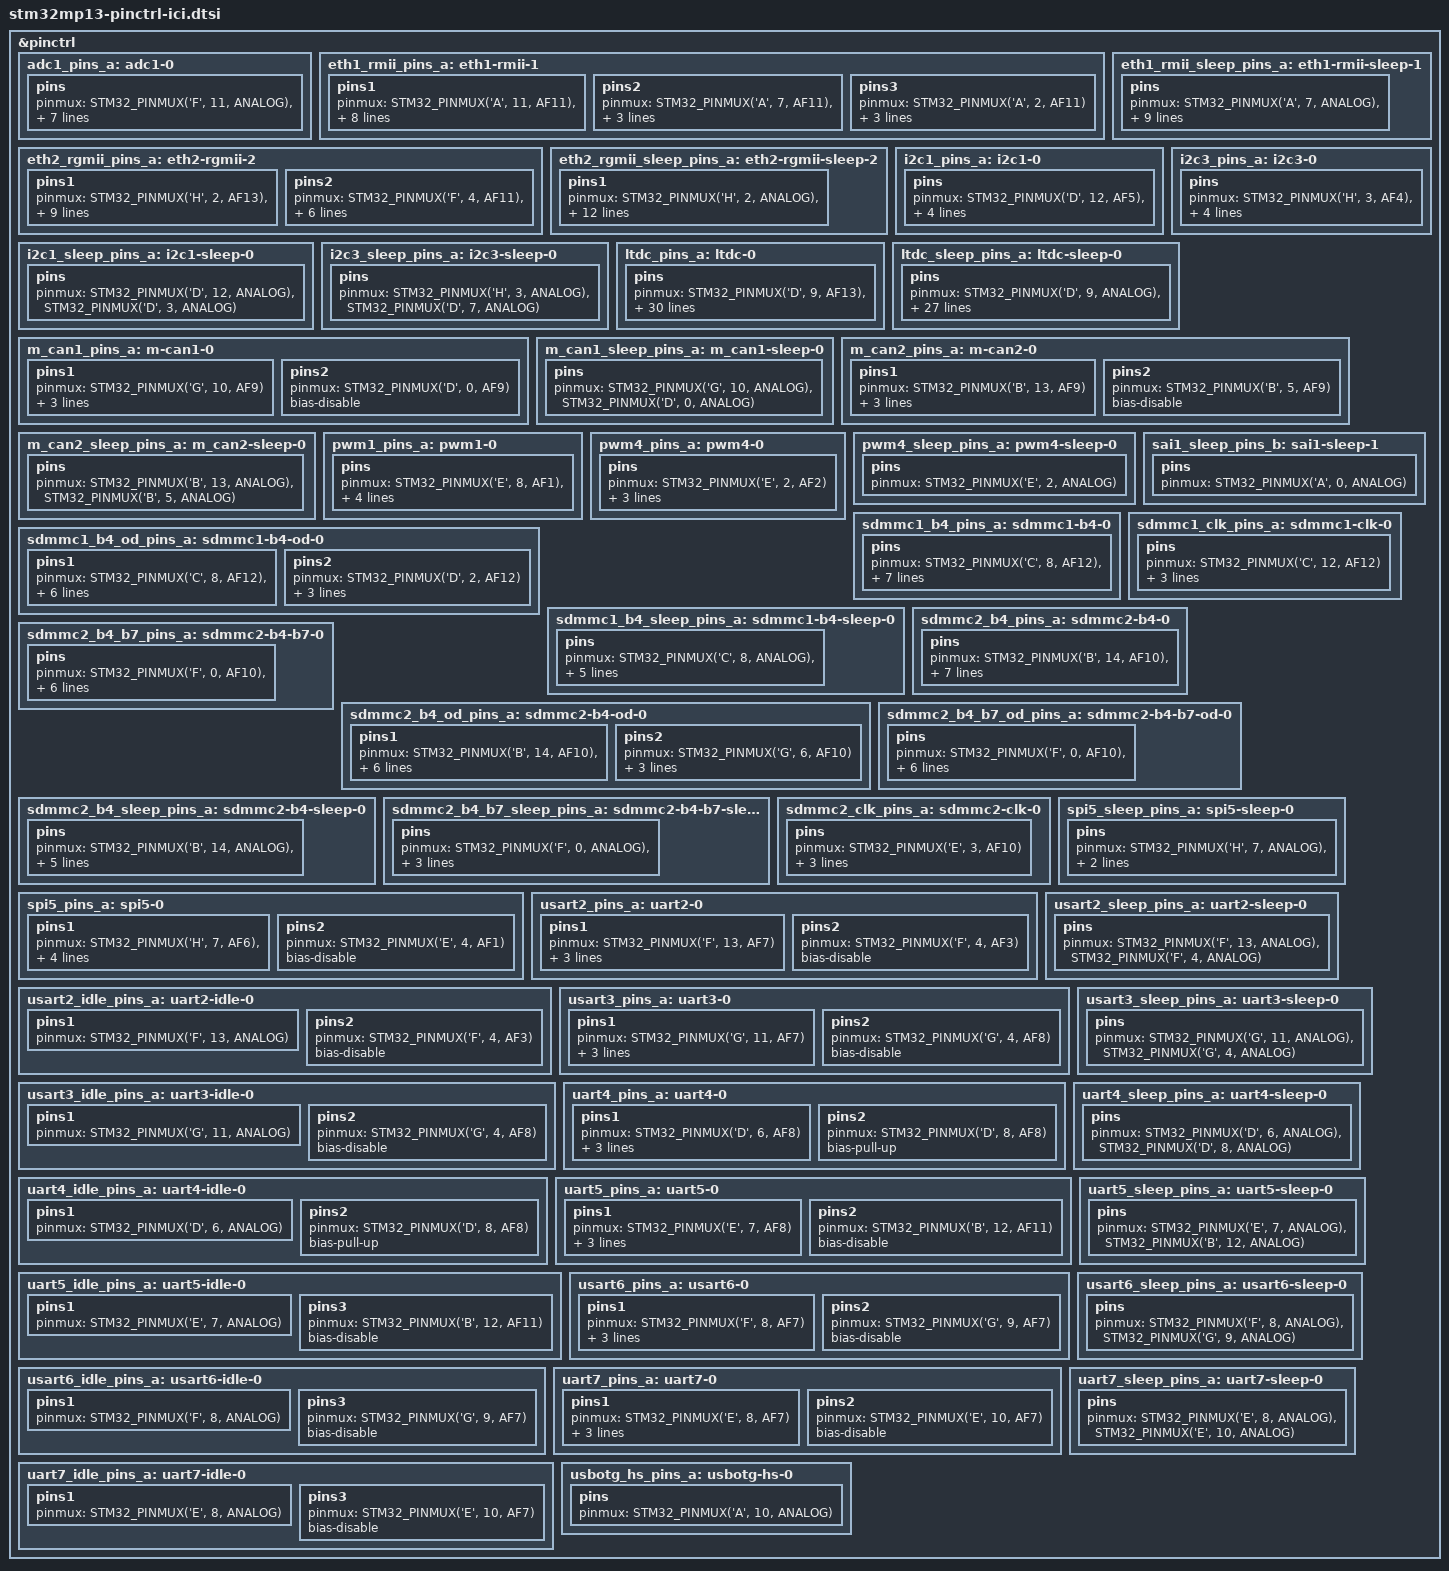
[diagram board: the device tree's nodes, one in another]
// SPDX-License-Identifier: (GPL-2.0+ OR BSD-3-Clause)
/*
 * Copyright (C) STMicroelectronics 2021 - All Rights Reserved
 * Author: Alexandre Torgue <alexandre.torgue@foss.st.com>
 */
#include <dt-bindings/pinctrl/stm32-pinfunc.h>

&pinctrl {
	adc1_pins_a: adc1-0 {
		pins {
			pinmux = <STM32_PINMUX('F', 11, ANALOG)>, /* ADC1 inp8 */
					<STM32_PINMUX('A', 0, ANALOG)>, /* ADC1 inp7 */
					<STM32_PINMUX('A', 5, ANALOG)>, /* ADC1 inp2 */
					<STM32_PINMUX('C', 0, ANALOG)>, /* ADC1 inp0 */
					<STM32_PINMUX('A', 4, ANALOG)>, /* ADC1 inp14 */
					<STM32_PINMUX('B', 1, ANALOG)>, /* ADC1 inp5 */
					<STM32_PINMUX('C', 3, ANALOG)>, /* ADC1 inp13 */
					<STM32_PINMUX('A', 3, ANALOG)>; /* ADC1 inp12 */
		};
	};

	eth1_rmii_pins_a: eth1-rmii-1 {
		pins1 {
			pinmux = <STM32_PINMUX('A', 11, AF11)>, /* ETH1_CLK */
					 <STM32_PINMUX('B', 11, AF11)>, /* ETH1_TX_EN */
					 <STM32_PINMUX('A', 1, AF11)>, /* ETH1_REF_CLK */
					 <STM32_PINMUX('G', 2, AF11)>, /* ETH1_MDC */
					 <STM32_PINMUX('G', 13, AF11)>, /* ETH1_TXD0 */
					 <STM32_PINMUX('G', 14, AF11)>; /* ETH1_TXD1 */
			bias-disable;
			drive-push-pull;
			slew-rate = <1>;
		};
		pins2 {
			pinmux = <STM32_PINMUX('A', 7, AF11)>, /* ETH1_CRS_DV */
					 <STM32_PINMUX('C', 4, AF11)>, /* ETH1_RXD0 */
					 <STM32_PINMUX('C', 5, AF11)>; /* ETH1_RXD1 */
			bias-disable;
		};
		pins3 {
			pinmux = <STM32_PINMUX('A', 2, AF11)>; /* ETH1_MDIO */
			bias-disable;
			drive-push-pull;
			slew-rate = <0>;
		};
	};

	eth1_rmii_sleep_pins_a: eth1-rmii-sleep-1 {
		pins {
			pinmux = <STM32_PINMUX('A', 7, ANALOG)>, /* ETH1_CRS_DV */
					 <STM32_PINMUX('A', 11, ANALOG)>, /* ETH1_CLK */
					 <STM32_PINMUX('B', 11, ANALOG)>, /* ETH1_TX_EN */
					 <STM32_PINMUX('C', 4, ANALOG)>, /* ETH1_RXD0 */
					 <STM32_PINMUX('C', 5, ANALOG)>, /* ETH1_RXD1 */
					 <STM32_PINMUX('A', 1, ANALOG)>, /* ETH1_REF_CLK */
					 <STM32_PINMUX('G', 2, ANALOG)>, /* ETH1_MDC */
					 <STM32_PINMUX('A', 2, ANALOG)>, /* ETH1_MDIO */
					 <STM32_PINMUX('G', 13, ANALOG)>, /* ETH1_TXD0 */
					 <STM32_PINMUX('G', 14, ANALOG)>; /* ETH1_TXD1 */
		};
	};

	eth2_rgmii_pins_a: eth2-rgmii-2 {
		pins1 {
			pinmux = <STM32_PINMUX('H', 2, AF13)>, /* ETH2_RGMII_CLK125 */
				 //<STM32_PINMUX('F', 7, AF11)>, 	/* ETH2_RGMII_TXD0 */
				 <STM32_PINMUX('G', 11, AF10)>, /* ETH2_RGMII_TXD1 */
				 <STM32_PINMUX('G', 1, AF10)>, 	/* ETH2_RGMII_TXD2 */
				 <STM32_PINMUX('E', 6, AF11)>, 	/* ETH2_RGMII_TXD3 */
				 <STM32_PINMUX('G', 3, AF10)>, 	/* ETH2_RGMII_GTX_CLK */
				 //<STM32_PINMUX('F', 6, AF11)>, 	/* ETH2_RGMII_TX_CTL */
				 <STM32_PINMUX('B', 2, AF11)>, 	/* ETH2_MDIO */
				 <STM32_PINMUX('G', 5, AF10)>; 	/* ETH2_MDC */
			bias-disable;
			drive-push-pull;
			slew-rate = <2>;
		};

		pins2 {
			pinmux = <STM32_PINMUX('F', 4, AF11)>, /* ETH2_RGMII_RXD0 */
				 <STM32_PINMUX('E', 2, AF10)>, 	/* ETH2_RGMII_RXD1 */
				 <STM32_PINMUX('H', 6, AF12)>, 	/* ETH2_RGMII_RXD2 */
				 <STM32_PINMUX('A', 8, AF11)>, 	/* ETH2_RGMII_RXD3 */
				 <STM32_PINMUX('H', 11, AF11)>, /* ETH2_RGMII_RX_CLK */
				 <STM32_PINMUX('G', 12, AF12)>; /* ETH2_RGMII_RX_CTL */
			bias-disable;
		};
	};

	eth2_rgmii_sleep_pins_a: eth2-rgmii-sleep-2 {
		pins1 {
			pinmux = <STM32_PINMUX('H', 2, ANALOG)>, /* ETH2_RGMII_CLK125 */
				 //<STM32_PINMUX('F', 7, ANALOG)>, 	/* ETH2_RGMII_TXD0 */
				 <STM32_PINMUX('G', 11, ANALOG)>, 	/* ETH2_RGMII_TXD1 */
				 <STM32_PINMUX('G', 1, ANALOG)>, 	/* ETH2_RGMII_TXD2 */
				 <STM32_PINMUX('E', 6, ANALOG)>, 	/* ETH2_RGMII_TXD3 */
				 <STM32_PINMUX('G', 3, ANALOG)>, 	/* ETH2_RGMII_GTX_CLK */
				 //<STM32_PINMUX('F', 6, ANALOG)>, 	/* ETH2_RGMII_TX_CTL */
				 <STM32_PINMUX('B', 2, ANALOG)>, 	/* ETH2_MDIO */
				 <STM32_PINMUX('G', 5, ANALOG)>, 	/* ETH2_MDC */
				 <STM32_PINMUX('F', 4, ANALOG)>, 	/* ETH2_RGMII_RXD0 */
				 <STM32_PINMUX('E', 2, ANALOG)>, 	/* ETH2_RGMII_RXD1 */
				 <STM32_PINMUX('H', 6, ANALOG)>, 	/* ETH2_RGMII_RXD2 */
				 <STM32_PINMUX('A', 8, ANALOG)>, 	/* ETH2_RGMII_RXD3 */
				 <STM32_PINMUX('H', 11, ANALOG)>, 	/* ETH2_RGMII_RX_CLK */
				 <STM32_PINMUX('G', 12, ANALOG)>; 	/* ETH2_RGMII_RX_CTL */
		};
	};

	i2c1_pins_a: i2c1-0 {
		pins {
			pinmux = <STM32_PINMUX('D', 12, AF5)>, /* I2C1_SCL */
				 <STM32_PINMUX('D', 3, AF5)>; /* I2C1_SDA */
			bias-disable;
			drive-open-drain;
			slew-rate = <0>;
		};
	};

	i2c1_sleep_pins_a: i2c1-sleep-0 {
		pins {
			pinmux = <STM32_PINMUX('D', 12, ANALOG)>, /* I2C1_SCL */
				 <STM32_PINMUX('D', 3, ANALOG)>; /* I2C1_SDA */
		};
	};

	i2c3_pins_a: i2c3-0 {
		pins {
			pinmux = <STM32_PINMUX('H', 3, AF4)>, /* I2C3_SCL */
				 <STM32_PINMUX('D', 7, AF5)>; /* I2C3_SDA */
			bias-disable;
			drive-open-drain;
			slew-rate = <0>;
		};
	};

	i2c3_sleep_pins_a: i2c3-sleep-0 {
		pins {
			pinmux = <STM32_PINMUX('H', 3, ANALOG)>, /* I2C3_SCL */
				 <STM32_PINMUX('D', 7, ANALOG)>; /* I2C3_SDA */
		};
	};

	ltdc_pins_a: ltdc-0 {
		pins {
			pinmux = <STM32_PINMUX('D',  9, AF13)>, /* LCD_CLK */
				 <STM32_PINMUX('H',  10, AF13)>, /* LCD_HSYNC */
				 <STM32_PINMUX('G',  4, AF11)>, /* LCD_VSYNC */ 
				 <STM32_PINMUX('H',  9, AF11)>, /* LCD_DE */
				 <STM32_PINMUX('E', 11, AF9)>,  /* LCD_R0 */
				 <STM32_PINMUX('D',  4, AF11)>, /* LCD_R1 */
				 <STM32_PINMUX('G',  7, AF14)>, /* LCD_R2 */
				 <STM32_PINMUX('B', 12, AF13)>, /* LCD_R3 */
				 <STM32_PINMUX('D', 14, AF14)>, /* LCD_R4 */
				 <STM32_PINMUX('E',  7, AF14)>, /* LCD_R5 */
				 <STM32_PINMUX('E', 13, AF14)>, /* LCD_R6 */
				 <STM32_PINMUX('E',  9, AF14)>, /* LCD_R7 */
				 <STM32_PINMUX('F',  5, AF9)>,  /* LCD_G0 */
				 <STM32_PINMUX('F',  1, AF14)>, /* LCD_G1 */
				 <STM32_PINMUX('H', 13, AF14)>, /* LCD_G2 */
				 <STM32_PINMUX('F',  3, AF14)>, /* LCD_G3 */
				 <STM32_PINMUX('E', 12, AF11)>, /* LCD_G4 */
				 <STM32_PINMUX('G',  0, AF14)>, /* LCD_G5 */
				 <STM32_PINMUX('A', 12, AF14)>, /* LCD_G6 */
				 <STM32_PINMUX('A', 15, AF11)>, /* LCD_G7 */
				 <STM32_PINMUX('D',  5, AF13)>, /* LCD_B0 */
				 <STM32_PINMUX('G',  8, AF7)>,  /* LCD_B1 */
				 <STM32_PINMUX('D', 10, AF14)>, /* LCD_B2 */
				 <STM32_PINMUX('F',  2, AF14)>, /* LCD_B3 */
				 <STM32_PINMUX('G', 15, AF11)>, /* LCD_B4 */
				 <STM32_PINMUX('D', 15, AF14)>, /* LCD_B5 */
				 <STM32_PINMUX('D',  1, AF11)>, /* LCD_B6 */
				 <STM32_PINMUX('E', 15, AF14)>; /* LCD_B7 */
			bias-disable;
			drive-push-pull;
			slew-rate = <1>;
		};
	};

	ltdc_sleep_pins_a: ltdc-sleep-0 {
		pins {
			pinmux = <STM32_PINMUX('D',  9, ANALOG)>, /* LCD_CLK */
				 <STM32_PINMUX('H',  10, ANALOG)>, /* LCD_HSYNC */
				 <STM32_PINMUX('G',  4, ANALOG)>, /* LCD_VSYNC */
				 <STM32_PINMUX('H',  9, ANALOG)>, /* LCD_DE */
				 <STM32_PINMUX('E', 11, ANALOG)>, /* LCD_R0 */
				 <STM32_PINMUX('D',  4, ANALOG)>, /* LCD_R1 */				 
				 <STM32_PINMUX('G',  7, ANALOG)>, /* LCD_R2 */
				 <STM32_PINMUX('B', 12, ANALOG)>, /* LCD_R3 */
				 <STM32_PINMUX('D', 14, ANALOG)>, /* LCD_R4 */
				 <STM32_PINMUX('E',  7, ANALOG)>, /* LCD_R5 */
				 <STM32_PINMUX('E', 13, ANALOG)>, /* LCD_R6 */
				 <STM32_PINMUX('E',  9, ANALOG)>, /* LCD_R7 */
				 <STM32_PINMUX('F',  5, ANALOG)>, /* LCD_G0 */
				 <STM32_PINMUX('F',  1, ANALOG)>, /* LCD_G1 */			 
				 <STM32_PINMUX('H', 13, ANALOG)>, /* LCD_G2 */
				 <STM32_PINMUX('F',  3, ANALOG)>, /* LCD_G3 */
				 <STM32_PINMUX('E', 12, ANALOG)>, /* LCD_G4 */
				 <STM32_PINMUX('G',  0, ANALOG)>, /* LCD_G5 */
				 <STM32_PINMUX('A', 12, ANALOG)>, /* LCD_G6 */
				 <STM32_PINMUX('A', 15, ANALOG)>, /* LCD_G7 */
				 <STM32_PINMUX('D',  5, ANALOG)>, /* LCD_B0 */
				 <STM32_PINMUX('G',  8, ANALOG)>, /* LCD_B1 */			 
				 <STM32_PINMUX('D', 10, ANALOG)>, /* LCD_B2 */
				 <STM32_PINMUX('F',  2, ANALOG)>, /* LCD_B3 */
				 <STM32_PINMUX('G', 15, ANALOG)>, /* LCD_B4 */
				 <STM32_PINMUX('D', 15, ANALOG)>, /* LCD_B5 */
				 <STM32_PINMUX('D',  1, ANALOG)>, /* LCD_B6 */
				 <STM32_PINMUX('E', 15, ANALOG)>; /* LCD_B7 */
		};
	};

	m_can1_pins_a: m-can1-0 {
		pins1 {
			pinmux = <STM32_PINMUX('G', 10, AF9)>; /* CAN1_TX */
			slew-rate = <1>;
			drive-push-pull;
			bias-disable;
		};
		pins2 {
			pinmux = <STM32_PINMUX('D', 0, AF9)>; /* CAN1_RX */
			bias-disable;
		};
	};

	m_can1_sleep_pins_a: m_can1-sleep-0 {
		pins {
			pinmux = <STM32_PINMUX('G', 10, ANALOG)>, /* CAN1_TX */
				 <STM32_PINMUX('D', 0, ANALOG)>; /* CAN1_RX */
		};
	};

	m_can2_pins_a: m-can2-0 {
		pins1 {
			pinmux = <STM32_PINMUX('B', 13, AF9)>; /* CAN2_TX */
			slew-rate = <1>;
			drive-push-pull;
			bias-disable;
		};
		pins2 {
			pinmux = <STM32_PINMUX('B', 5, AF9)>; /* CAN2_RX */
			bias-disable;
		};
	};

	m_can2_sleep_pins_a: m_can2-sleep-0 {
		pins {
			pinmux = <STM32_PINMUX('B', 13, ANALOG)>, /* CAN2_TX */
				 <STM32_PINMUX('B', 5, ANALOG)>; /* CAN2_RX */
		};
	};

	pwm1_pins_a: pwm1-0 {
		pins {
			pinmux = <STM32_PINMUX('E', 8, AF1)>, /* TIM1_CH1N */
                   <STM32_PINMUX('F', 9, AF2)>; /* TIM1_CH1 */
			bias-pull-down;
			drive-push-pull;
			slew-rate = <0>;
		};
	};


	pwm4_pins_a: pwm4-0 {
		pins {
			pinmux = <STM32_PINMUX('E', 2, AF2)>; /* TIM4_CH2 */
			bias-pull-down;
			drive-push-pull;
			slew-rate = <0>;
		};
	};

	pwm4_sleep_pins_a: pwm4-sleep-0 {
		pins {
			pinmux = <STM32_PINMUX('E', 2, ANALOG)>; /* TIM4_CH2 */
		};
	};

	sai1_sleep_pins_b: sai1-sleep-1 {
		pins {
			pinmux = <STM32_PINMUX('A', 0, ANALOG)>; /* SAI1_SD_B */
		};
	};

	sdmmc1_b4_pins_a: sdmmc1-b4-0 {
		pins {
			pinmux = <STM32_PINMUX('C', 8, AF12)>, /* SDMMC1_D0 */
				 <STM32_PINMUX('C', 9, AF12)>, /* SDMMC1_D1 */
				 <STM32_PINMUX('C', 10, AF12)>, /* SDMMC1_D2 */
				 <STM32_PINMUX('C', 11, AF12)>, /* SDMMC1_D3 */
				 <STM32_PINMUX('D', 2, AF12)>; /* SDMMC1_CMD */
			slew-rate = <1>;
			drive-push-pull;
			bias-disable;
		};
	};

	sdmmc1_b4_od_pins_a: sdmmc1-b4-od-0 {
		pins1 {
			pinmux = <STM32_PINMUX('C', 8, AF12)>, /* SDMMC1_D0 */
				 <STM32_PINMUX('C', 9, AF12)>, /* SDMMC1_D1 */
				 <STM32_PINMUX('C', 10, AF12)>, /* SDMMC1_D2 */
				 <STM32_PINMUX('C', 11, AF12)>; /* SDMMC1_D3 */
			slew-rate = <1>;
			drive-push-pull;
			bias-disable;
		};
		pins2 {
			pinmux = <STM32_PINMUX('D', 2, AF12)>; /* SDMMC1_CMD */
			slew-rate = <1>;
			drive-open-drain;
			bias-disable;
		};
	};

	sdmmc1_b4_sleep_pins_a: sdmmc1-b4-sleep-0 {
		pins {
			pinmux = <STM32_PINMUX('C', 8, ANALOG)>, /* SDMMC1_D0 */
				 <STM32_PINMUX('C', 9, ANALOG)>, /* SDMMC1_D1 */
				 <STM32_PINMUX('C', 10, ANALOG)>, /* SDMMC1_D2 */
				 <STM32_PINMUX('C', 11, ANALOG)>, /* SDMMC1_D3 */
				 <STM32_PINMUX('C', 12, ANALOG)>, /* SDMMC1_CK */
				 <STM32_PINMUX('D', 2, ANALOG)>; /* SDMMC1_CMD */
		};
	};

	sdmmc1_clk_pins_a: sdmmc1-clk-0 {
		pins {
			pinmux = <STM32_PINMUX('C', 12, AF12)>; /* SDMMC1_CK */
			slew-rate = <1>;
			drive-push-pull;
			bias-disable;
		};
	};

	sdmmc2_b4_pins_a: sdmmc2-b4-0 {
		pins {
			pinmux = <STM32_PINMUX('B', 14, AF10)>, /* SDMMC2_D0 */
				 <STM32_PINMUX('B', 15, AF10)>, /* SDMMC2_D1 */
				 <STM32_PINMUX('B', 3, AF10)>, /* SDMMC2_D2 */
				 <STM32_PINMUX('B', 4, AF10)>, /* SDMMC2_D3 */
				 <STM32_PINMUX('G', 6, AF10)>; /* SDMMC2_CMD */
			slew-rate = <1>;
			drive-push-pull;
			bias-pull-up;
		};
	};

	sdmmc2_b4_b7_pins_a: sdmmc2-b4-b7-0 {
		pins {
			pinmux = <STM32_PINMUX('F', 0, AF10)>, /* SDMMC2_D4 */
				 <STM32_PINMUX('B', 9, AF10)>, /* SDMMC2_D5 */
				 <STM32_PINMUX('C', 6, AF10)>, /* SDMMC2_D6 */				 
				 <STM32_PINMUX('C', 7, AF10)>; /* SDMMC2_D7 */
			slew-rate = <1>;
			drive-push-pull;
			bias-pull-up;
		};
	};

	sdmmc2_b4_od_pins_a: sdmmc2-b4-od-0 {
		pins1 {
			pinmux = <STM32_PINMUX('B', 14, AF10)>, /* SDMMC2_D0 */
				 <STM32_PINMUX('B', 15, AF10)>, /* SDMMC2_D1 */
				 <STM32_PINMUX('B', 3, AF10)>, /* SDMMC2_D2 */
				 <STM32_PINMUX('B', 4, AF10)>; /* SDMMC2_D3 */
			slew-rate = <1>;
			drive-push-pull;
			bias-pull-up;
		};
		pins2 {
			pinmux = <STM32_PINMUX('G', 6, AF10)>; /* SDMMC2_CMD */
			slew-rate = <1>;
			drive-open-drain;
			bias-pull-up;
		};
	};

	sdmmc2_b4_b7_od_pins_a: sdmmc2-b4-b7-od-0 {
		pins {
			pinmux = <STM32_PINMUX('F', 0, AF10)>, /* SDMMC2_D4 */
				 <STM32_PINMUX('B', 9, AF10)>, /* SDMMC2_D5 */
				 <STM32_PINMUX('C', 6, AF10)>, /* SDMMC2_D6 */				 
				 <STM32_PINMUX('C', 7, AF10)>; /* SDMMC2_D7 */
			slew-rate = <1>;
			drive-push-pull;
			bias-pull-up;
		};
	};	

	sdmmc2_b4_sleep_pins_a: sdmmc2-b4-sleep-0 {
		pins {
			pinmux = <STM32_PINMUX('B', 14, ANALOG)>, /* SDMMC2_D0 */
				 <STM32_PINMUX('B', 15, ANALOG)>, /* SDMMC2_D1 */
				 <STM32_PINMUX('B', 3, ANALOG)>, /* SDMMC2_D2 */
				 <STM32_PINMUX('B', 4, ANALOG)>, /* SDMMC2_D3 */
				 <STM32_PINMUX('E', 3, ANALOG)>, /* SDMMC2_CK */
				 <STM32_PINMUX('G', 6, ANALOG)>; /* SDMMC2_CMD */
		};
	};

	sdmmc2_b4_b7_sleep_pins_a: sdmmc2-b4-b7-sleep-0 {
		pins {
			pinmux = <STM32_PINMUX('F', 0, ANALOG)>, /* SDMMC2_D4 */
				 <STM32_PINMUX('B', 9, ANALOG)>, /* SDMMC2_D5 */
				 <STM32_PINMUX('C', 6, ANALOG)>, /* SDMMC2_D6 */				 
				 <STM32_PINMUX('C', 7, ANALOG)>; /* SDMMC2_D7 */
		};
	};

	sdmmc2_clk_pins_a: sdmmc2-clk-0 {
		pins {
			pinmux = <STM32_PINMUX('E', 3, AF10)>; /* SDMMC2_CK */
			slew-rate = <1>;
			drive-push-pull;
			bias-pull-up;
		};
	};

	spi5_pins_a: spi5-0 {
		pins1 {
			pinmux = <STM32_PINMUX('H', 7, AF6)>, /* SPI5_SCK */
				 <STM32_PINMUX('H', 12, AF5)>; /* SPI5_MOSI */
			bias-disable;
			drive-push-pull;
			slew-rate = <1>;
		};

		pins2 {
			pinmux = <STM32_PINMUX('E', 4, AF1)>; /* SPI5_MISO */
			bias-disable;
		};
	};

	spi5_sleep_pins_a: spi5-sleep-0 {
		pins {
			pinmux = <STM32_PINMUX('H', 7, ANALOG)>, /* SPI5_SCK */
				 <STM32_PINMUX('E', 4, ANALOG)>, /* SPI5_MISO */
				 <STM32_PINMUX('H', 12, ANALOG)>; /* SPI5_MOSI */
		};
	};

	usart2_pins_a: uart2-0 {
		pins1 {
			pinmux = <STM32_PINMUX('F', 13, AF7)>; /* UART2_TX */
			bias-disable;
			drive-push-pull;
			slew-rate = <0>;
		};
		pins2 {
			pinmux = <STM32_PINMUX('F', 4, AF3)>; /* UART2_RX */
			bias-disable;
		};
	};

	usart2_idle_pins_a: uart2-idle-0 {
		pins1 {
			pinmux = <STM32_PINMUX('F', 13, ANALOG)>; /* UART2_TX */
		};
		pins2 {
			pinmux = <STM32_PINMUX('F', 4, AF3)>; /* UART2_RX */
			bias-disable;
		};
	};

	usart2_sleep_pins_a: uart2-sleep-0 {
		pins {
			pinmux = <STM32_PINMUX('F', 13, ANALOG)>, /* UART2_TX */
				 <STM32_PINMUX('F', 4, ANALOG)>; /* UART2_RX */
		};
	};

	usart3_pins_a: uart3-0 {
		pins1 {
			pinmux = <STM32_PINMUX('G', 11, AF7)>; /* UART3_TX */
			bias-disable;
			drive-push-pull;
			slew-rate = <0>;
		};
		pins2 {
			pinmux = <STM32_PINMUX('G', 4, AF8)>; /* UART3_RX */
			bias-disable;
		};
	};

	usart3_idle_pins_a: uart3-idle-0 {
		pins1 {
			pinmux = <STM32_PINMUX('G', 11, ANALOG)>; /* UART3_TX */
		};
		pins2 {
			pinmux = <STM32_PINMUX('G', 4, AF8)>; /* UART3_RX */
			bias-disable;
		};
	};

	usart3_sleep_pins_a: uart3-sleep-0 {
		pins {
			pinmux = <STM32_PINMUX('G', 11, ANALOG)>, /* UART3_TX */
				 <STM32_PINMUX('G', 4, ANALOG)>; /* UART3_RX */
		};
	};

	uart4_pins_a: uart4-0 {
		pins1 {
			pinmux = <STM32_PINMUX('D', 6, AF8)>; /* UART4_TX */
			bias-disable;
			drive-push-pull;
			slew-rate = <0>;
		};
		pins2 {
			pinmux = <STM32_PINMUX('D', 8, AF8)>; /* UART4_RX */
			bias-pull-up;
		};
	};

	uart4_idle_pins_a: uart4-idle-0 {
		pins1 {
			pinmux = <STM32_PINMUX('D', 6, ANALOG)>; /* UART4_TX */
		};
		pins2 {
			pinmux = <STM32_PINMUX('D', 8, AF8)>; /* UART4_RX */
			bias-pull-up;
		};
	};

	uart4_sleep_pins_a: uart4-sleep-0 {
		pins {
			pinmux = <STM32_PINMUX('D', 6, ANALOG)>, /* UART4_TX */
				 <STM32_PINMUX('D', 8, ANALOG)>; /* UART4_RX */
		};
	};

	uart5_pins_a: uart5-0 {
		pins1 {
			pinmux = <STM32_PINMUX('E', 7, AF8)>; /* UART5_TX */
			bias-disable;
			drive-push-pull;
			slew-rate = <0>;
		};
		pins2 {
			pinmux = <STM32_PINMUX('B', 12, AF11)>; /* UART5_RX */
			bias-disable;
		};
	};

	uart5_idle_pins_a: uart5-idle-0 {
		pins1 {
			pinmux = <STM32_PINMUX('E', 7, ANALOG)>; /* UART5_TX */
		};
		pins3 {
			pinmux = <STM32_PINMUX('B', 12, AF11)>; /* UART5_RX */
			bias-disable;
		};
	};

	uart5_sleep_pins_a: uart5-sleep-0 {
		pins {
			pinmux = <STM32_PINMUX('E', 7, ANALOG)>, /* UART5_TX */
				 <STM32_PINMUX('B', 12, ANALOG)>; /* UART5_RX */
		};
	};

	usart6_pins_a: usart6-0 {
		pins1 {
			pinmux = <STM32_PINMUX('F', 8, AF7)>; /* UART6_TX */
			bias-disable;
			drive-push-pull;
			slew-rate = <0>;
		};
		pins2 {
			pinmux = <STM32_PINMUX('G', 9, AF7)>; /* UART6_RX */
			bias-disable;
		};
	};

	usart6_idle_pins_a: usart6-idle-0 {
		pins1 {
			pinmux = <STM32_PINMUX('F', 8, ANALOG)>; /* UART6_TX */
		};
		pins3 {
			pinmux = <STM32_PINMUX('G', 9, AF7)>; /* UART6_RX */
			bias-disable;
		};
	};

	usart6_sleep_pins_a: usart6-sleep-0 {
		pins {
			pinmux = <STM32_PINMUX('F', 8, ANALOG)>, /* UART6_TX */
				 <STM32_PINMUX('G', 9, ANALOG)>; /* UART6_RX */
		};
	};

	uart7_pins_a: uart7-0 {
		pins1 {
			pinmux = <STM32_PINMUX('E', 8, AF7)>; /* UART7_TX */
			bias-disable;
			drive-push-pull;
			slew-rate = <0>;
		};
		pins2 {
			pinmux = <STM32_PINMUX('E', 10, AF7)>; /* UART7_RX */
			bias-disable;
		};
	};

	uart7_idle_pins_a: uart7-idle-0 {
		pins1 {
			pinmux = <STM32_PINMUX('E', 8, ANALOG)>; /* UART7_TX */
		};
		pins3 {
			pinmux = <STM32_PINMUX('E', 10, AF7)>; /* UART7_RX */
			bias-disable;
		};
	};

	uart7_sleep_pins_a: uart7-sleep-0 {
		pins {
			pinmux = <STM32_PINMUX('E', 8, ANALOG)>, /* UART7_TX */
				 <STM32_PINMUX('E', 10, ANALOG)>; /* UART7_RX */
		};
	};

	usbotg_hs_pins_a: usbotg-hs-0 {
		pins {
			pinmux = <STM32_PINMUX('A', 10, ANALOG)>; /* OTG_ID */
		};
	};
};
